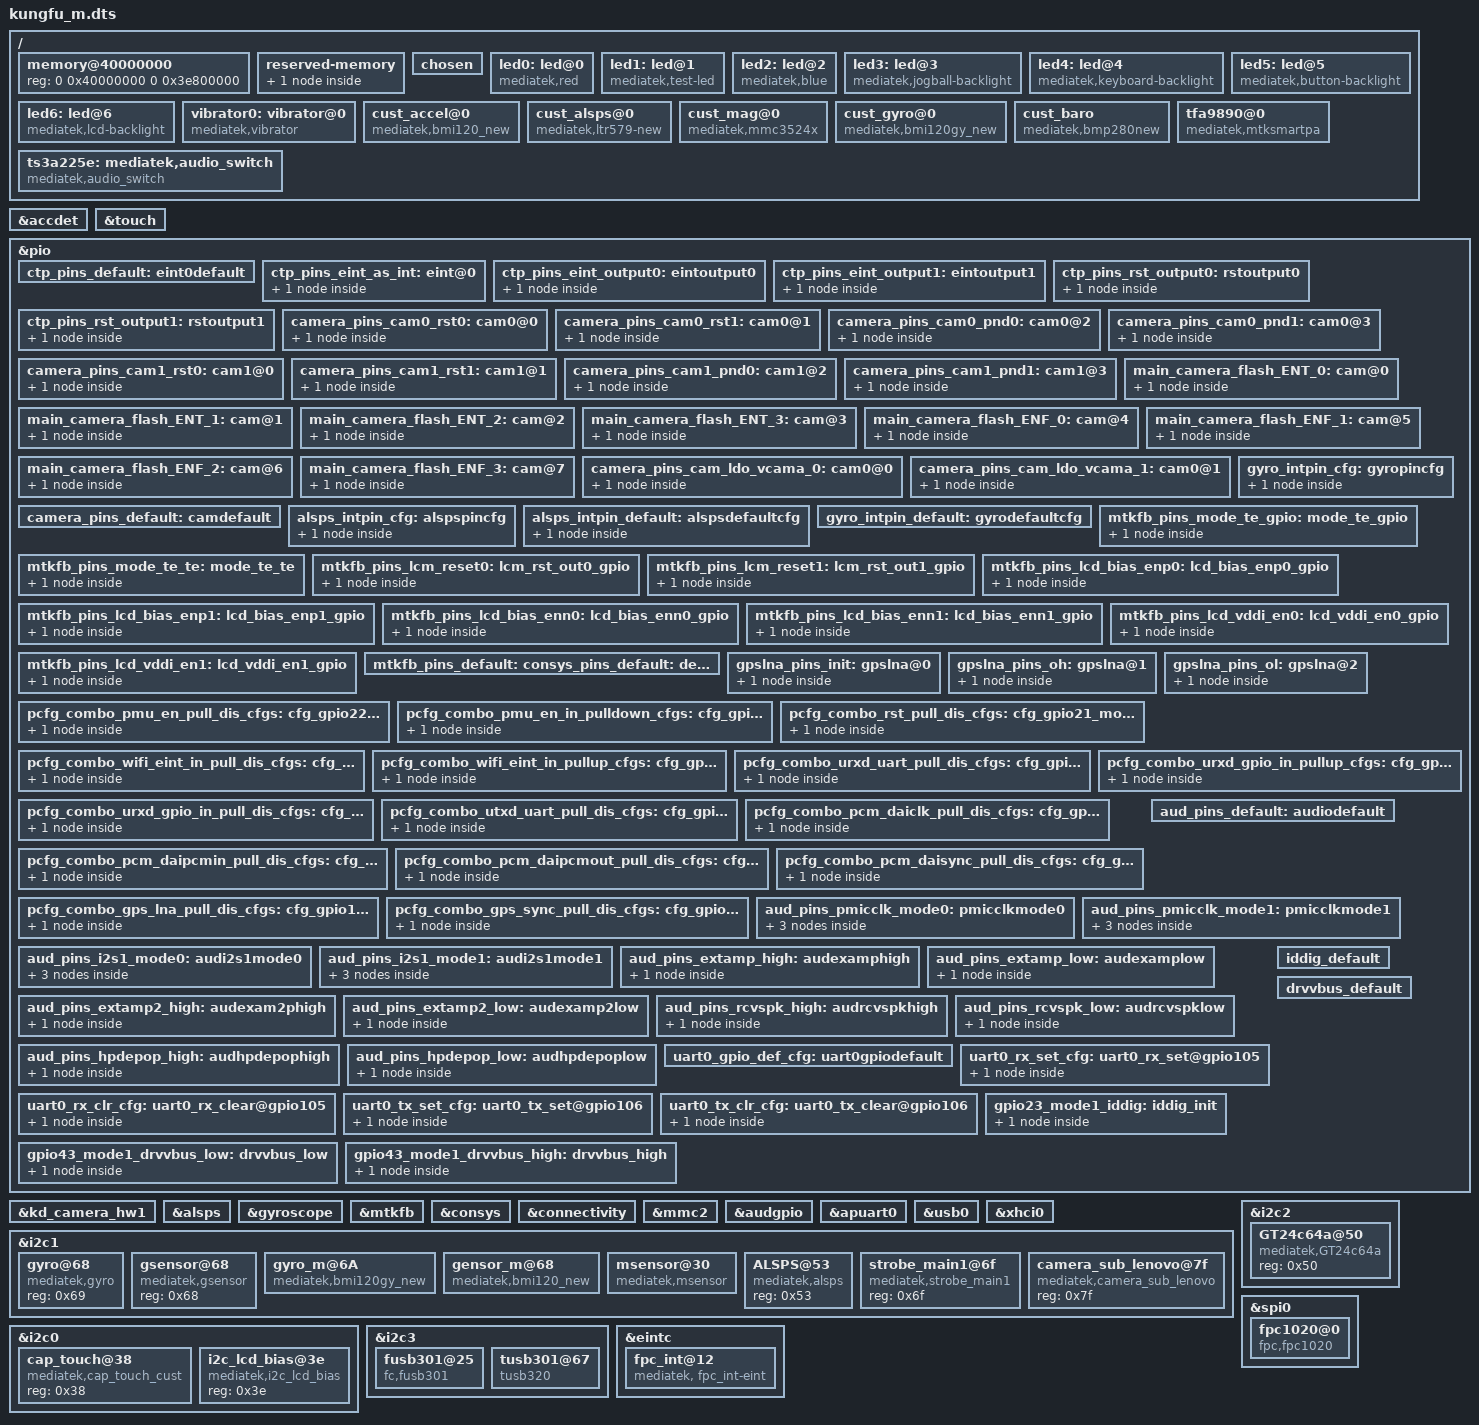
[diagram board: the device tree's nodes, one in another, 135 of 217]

/dts-v1/;

#include "mt6755.dtsi"
#include "cust.dtsi"

/ {
	memory@40000000 {
		device_type = "memory";
		reg = <0 0x40000000 0 0x3e800000>;
	};
	reserved-memory {
		#address-cells = <2>;
		#size-cells = <2>;
		ranges;

		reserve-memory-ccci_md3_ccif {
			compatible = "mediatek,reserve-memory-ccci_md3_ccif";
			no-map;
			size = <0 0x01000000>;
			alignment = <0 0x2000000>;
			alloc-ranges = <0 0x40000000 0 0xc0000000>;
		};
	};

	/* chosen */
	chosen {
		bootargs = "console=tty0 console=ttyMT0,921600n1 root=/dev/ram initrd=0x44000000,0x4B434E loglevel=8";

		/* fpga may has no lk, we need to specify display info here */
		/* fb buffer is reserved using this dts by memory node above */
		atag,videolfb-fb_base_h = <0x0>;
		atag,videolfb-fb_base_l = <0x7E800000>;
		atag,videolfb-islcmfound = <1>;
		/* because no lk, so lcm is not inited */
		atag,videolfb-islcm_inited = <0>;
		atag,videolfb-fps= <6000>;
		atag,videolfb-vramSize= <0x01800000>;
		atag,videolfb-lcmname= "nt35695_fhd_dsi_cmd_truly_nt50358_drv";
	};
	led0:led@0 {
		compatible = "mediatek,red";
		led_mode = <0>;
		data = <1>;
		pwm_config = <0 0 0 0 0>;
	};
	led1:led@1 {
		compatible = "mediatek,test-led";
		led_mode = <3>;
		data = <1>;
		pwm_config = <0 0 0 0 0>;
	};
	led2:led@2 {
		compatible = "mediatek,blue";
		led_mode = <0>;
		data = <2>;
		pwm_config = <0 0 0 0 0>;
	};
	led3:led@3 {
		compatible = "mediatek,jogball-backlight";
		led_mode = <0>;
		data = <1>;
		pwm_config = <0 0 0 0 0>;
	};
	led4:led@4 {
		compatible = "mediatek,keyboard-backlight";
		led_mode = <0>;
		data = <1>;
		pwm_config = <0 0 0 0 0>;
	};
	led5:led@5 {
		compatible = "mediatek,button-backlight";
		led_mode = <0>;
		data = <3>;
		pwm_config = <0 0 0 0 0>;
	};
	led6:led@6 {
		compatible = "mediatek,lcd-backlight";
		led_mode = <4>;/* lenovo-sw wuwl10 20160322 modify */
		data = <1>;
		pwm_config = <0 0 0 0 0>;
	};
	vibrator0:vibrator@0 {
		compatible = "mediatek,vibrator";
		vib_timer = <25>;
		vib_limit = <9>;
		vib_vol= <6>;
	};
/*  start sensor */
/* Lenovo-sw, weimh1, 2016-3-31 add begin: configure gsensor cust_accel */
	cust_accel@0 {
		compatible = "mediatek,bmi120_new";
		i2c_num	= <1>;
		i2c_addr = <0x6A 0 0 0>;   /*false addr,real is 0x68*/
		direction = <2>;
		power_id = <0xffff>;
		power_vol = <0>;
		firlen = <0>;
		is_batch_supported = <0>;
	};
/* Lenovo-sw, weimh1, 2016-3-31 add end: configure gsensor cust_accel */

	/*Begin, lenovo-sw lumy1*/
	cust_alsps@0 {
		compatible		= "mediatek,ltr579-new";
		i2c_num			= <1>;
		i2c_addr		= <0x53 0 0 0>;
		polling_mode_ps		= <0>;
		polling_mode_als	= <1>;
		power_id		= <0xffff>;
		power_vol		= <0>;
/* Total has 15 level*/
		als_level     = <0 3 10 30 100 200 350 500 800 1200 2000 4000 10000 30000 57937>;
/*  Total has 16 range*/
		als_value   = <0 1 8 26 80 170 320 450 730 1020 1800 3600  8500 26000 40000 40000>;
		ps_threshold_high	=  <200>;
		ps_threshold_low	=  <120>;
		is_batch_supported_ps	= <1>;
		is_batch_supported_als	= <1>;
	};
	/*End, lenovo-sw lumy1*/

/*lenovo-sw caoyi1 modify Msensor begin*/
	cust_mag@0 {
		compatible			= "mediatek,mmc3524x";
		i2c_num				= <1>;
		i2c_addr			= <0x30 0 0 0>;
		direction			= <4>;
		power_id			= <0xffff>;
		power_vol			= <0>;
		/* is_batch_supported		= <0>; */
	};
/*lenovo-sw caoyi1 modify Msensor end*/

/* Lenovo-sw, weimh1, 2016-4-4 add begin: configure gyroscope cust_gyro */
	cust_gyro@0 {
		compatible				= "mediatek,bmi120gy_new";
		i2c_num					= <1>;
		i2c_addr				= <0x68 0 0 0>;
		direction				= <2>;
		power_id				= <0xffff>;
		power_vol				= <0>;
		firlen					= <0>;
		is_batch_supported			= <0>;
	};
/* Lenovo-sw, weimh1, 2016-4-4 add end: configure gyroscope cust_gyro */

	cust_baro {
		compatible			= "mediatek,bmp280new";
		i2c_num				= <1>;
		/* i2c_addr			= <0x68 0 0 0>; */
		direction			= <0>;
		power_id			= <0xffff>;
		power_vol			= <0>;
		firlen				= <32>;
		is_batch_supported		= <0>;
	};
/* end sensor */
/* Lenovo-sw, chengx2, 2016-4-20 add for smartpa start */
	tfa9890@0 {
			compatible = "mediatek,mtksmartpa";
			
		};
	ts3a225e:mediatek,audio_switch {
			compatible = "mediatek,audio_switch";
		};

/* Lenovo-sw, chengx2, 2016-4-20 add for smartpa end */

};
&accdet {
		accdet-mic-vol = <7>;
		headset-mode-setting = <0x500 0x500 1 0x3F0 0x800 0x800 0x2000>;
		accdet-plugout-debounce = <20>;
		/*1:ACC mode, 2:low cost without in bias, 6:low cost with in bias*/
		accdet-mic-mode = <1>;
		/*0--MD_MAX--UP_MAX--DW_MAX*/
		headset-three-key-threshold = <0 80 200 500>;
		/*0--MD_MAX--VOICE_MAX--UP_MAX--DW_MAX*/
		headset-four-key-threshold = <0 58 121 192 450>;
};

/* TOUCH start */
&touch {
	tpd-resolution = <1080 1920>;
	interrupt-parent = <&eintc>;
	interrupts = <1 2>;
	debounce = <1 0>;
	use-tpd-button = <1>;
	tpd-key-num = <3>;
	tpd-key-local= <139 172 158 0>;
	tpd-key-dim-local = <90 883 100 40 230 883 100 40 370 883 100 40 0 0 0 0>;
	tpd-max-touch-num = <5>;
	tpd-filter-enable = <1>;
	tpd-filter-pixel-density = <146>;
	tpd-filter-custom-prameters = <0 0 0 0 0 0 0 0 0 0 0 0>;
	tpd-filter-custom-speed = <0 0 0>;
	pinctrl-names = "default", "state_eint_as_int", "state_eint_output0", "state_eint_output1",
		"state_rst_output0", "state_rst_output1";
	pinctrl-0 = <&ctp_pins_default>;
	pinctrl-1 = <&ctp_pins_eint_as_int>;
	pinctrl-2 = <&ctp_pins_eint_output0>;
	pinctrl-3 = <&ctp_pins_eint_output1>;
	pinctrl-4 = <&ctp_pins_rst_output0>;
	pinctrl-5 = <&ctp_pins_rst_output1>;
	status = "okay";
};
&pio {
	ctp_pins_default: eint0default {
	};
	ctp_pins_eint_as_int: eint@0 {
		pins_cmd_dat {
			pins = <PINMUX_GPIO1__FUNC_GPIO1>;
			slew-rate = <0>;
			bias-disable;
		};
	};
	ctp_pins_eint_output0: eintoutput0 {
		pins_cmd_dat {
			pins = <PINMUX_GPIO1__FUNC_GPIO1>;
			slew-rate = <1>;
			output-low;
		};
	};
	ctp_pins_eint_output1: eintoutput1 {
		pins_cmd_dat {
			pins = <PINMUX_GPIO1__FUNC_GPIO1>;
			slew-rate = <1>;
			output-high;
		};
	};
	ctp_pins_rst_output0: rstoutput0 {
		pins_cmd_dat {
			pins = <PINMUX_GPIO10__FUNC_GPIO10>;
			slew-rate = <1>;
			output-low;
		};
	};
	ctp_pins_rst_output1: rstoutput1 {
		pins_cmd_dat {
			pins = <PINMUX_GPIO10__FUNC_GPIO10>;
			slew-rate = <1>;
			output-high;
		};
	};
};
/* TOUCH end */

/* CAMERA GPIO standardization */
&pio {
	camera_pins_cam0_rst0: cam0@0 {
	    pins_cmd_dat {
			pins = <PINMUX_GPIO107__FUNC_GPIO107>;
			slew-rate = <1>; /*direction 0:in, 1:out*/
			output-low;/*direction out used only. output_low or high*/
		};
	};
	camera_pins_cam0_rst1: cam0@1 {
	    pins_cmd_dat {
			pins = <PINMUX_GPIO107__FUNC_GPIO107>;
			slew-rate = <1>;
			output-high;
		};
	};
	camera_pins_cam0_pnd0: cam0@2 {
	    pins_cmd_dat {
			pins = <PINMUX_GPIO110__FUNC_GPIO110>;
			slew-rate = <1>;
			output-low;
		};
	};
	camera_pins_cam0_pnd1: cam0@3 {
	    pins_cmd_dat {
			pins = <PINMUX_GPIO110__FUNC_GPIO110>;
			slew-rate = <1>;
			output-high;
		};
	};
	camera_pins_cam1_rst0: cam1@0 {
	    pins_cmd_dat {
			pins = <PINMUX_GPIO108__FUNC_GPIO108>;
			slew-rate = <1>; /*direction 0:in, 1:out*/
			output-low;/*direction out used only. output_low or high*/
		};
	};
	camera_pins_cam1_rst1: cam1@1 {
	    pins_cmd_dat {
			pins = <PINMUX_GPIO108__FUNC_GPIO108>;
			slew-rate = <1>;
			output-high;
		};
	};
	camera_pins_cam1_pnd0: cam1@2 {
	    pins_cmd_dat {
			pins = <PINMUX_GPIO111__FUNC_GPIO111>;
			slew-rate = <1>;
			output-low;
		};
	};
	camera_pins_cam1_pnd1: cam1@3 {
	    pins_cmd_dat {
			pins = <PINMUX_GPIO111__FUNC_GPIO111>;
			slew-rate = <1>;
			output-high;
		};
	};
	main_camera_flash_ENT_0: cam@0 {
		pins_cmd_dat {
			pins = <PINMUX_GPIO8__FUNC_GPIO8>;
			slew-rate = <1>;
			output-low;
		};
	};
	main_camera_flash_ENT_1: cam@1 {
		pins_cmd_dat {
			pins = <PINMUX_GPIO8__FUNC_GPIO8>;
			slew-rate = <1>;
			output-high;
		};
	};
	main_camera_flash_ENT_2: cam@2 {
		pins_cmd_dat {
			pins = <PINMUX_GPIO9__FUNC_GPIO9>;
			slew-rate = <1>;
			output-low;
                };
	};
	main_camera_flash_ENT_3: cam@3 {
		pins_cmd_dat {
			pins = <PINMUX_GPIO9__FUNC_GPIO9>;
			slew-rate = <1>;
			output-high;
                };
	};
	main_camera_flash_ENF_0: cam@4{
		pins_cmd_dat {
			pins = <PINMUX_GPIO19__FUNC_GPIO19>;
			slew-rate = <1>;
			output-low;
		};
	};
	main_camera_flash_ENF_1: cam@5 {
		pins_cmd_dat {
			pins = <PINMUX_GPIO19__FUNC_GPIO19>;
			slew-rate = <1>;
			output-high;
		};
	};
	main_camera_flash_ENF_2: cam@6 {
		pins_cmd_dat {
			pins = <PINMUX_GPIO9__FUNC_GPIO9>;
			slew-rate = <1>;
			output-low;
		};
	};
	main_camera_flash_ENF_3: cam@7{
		pins_cmd_dat {
			pins = <PINMUX_GPIO9__FUNC_GPIO9>;
			slew-rate = <1>;
			output-high;
		};
	};
camera_pins_cam_ldo_vcama_0: cam0@0 {
	    pins_cmd_dat {
			pins = <PINMUX_GPIO83__FUNC_GPIO83>;
			slew-rate = <1>; /*direction 0:in, 1:out*/
			output-low;/*direction out used only. output_low or high*/
		};
	};
	camera_pins_cam_ldo_vcama_1: cam0@1 {
	    pins_cmd_dat {
			pins = <PINMUX_GPIO83__FUNC_GPIO83>;
			slew-rate = <1>;
			output-high;
		};
	};
	camera_pins_default: camdefault {
	};

};

&kd_camera_hw1 {
	pinctrl-names = "default",
			"cam0_rst0", "cam0_rst1", "cam0_pnd0", "cam0_pnd1",
			"cam1_rst0", "cam1_rst1", "cam1_pnd0", "cam1_pnd1",
			"flash_ENT0", "flash_ENT1", "flash_ENT2", "flash_ENT3","flash_ENF0", "flash_ENF1","flash_ENF2", "flash_ENF3","cam_ldo_vcama_0", "cam_ldo_vcama_1";
			/*"cam2_rst0", "cam2_rst1", "cam2_pnd0", "cam2_pnd1",
			"cam_ldo_vcama_0", "cam_ldo_vcama_1";*/
	pinctrl-0 = <&camera_pins_default>;
	pinctrl-1 = <&camera_pins_cam0_rst0>;
	pinctrl-2 = <&camera_pins_cam0_rst1>;
	pinctrl-3 = <&camera_pins_cam0_pnd0>;
	pinctrl-4 = <&camera_pins_cam0_pnd1>;
	pinctrl-5 = <&camera_pins_cam1_rst0>;
	pinctrl-6 = <&camera_pins_cam1_rst1>;
	pinctrl-7 = <&camera_pins_cam1_pnd0>;
	pinctrl-8 = <&camera_pins_cam1_pnd1>;
	pinctrl-9 = <&main_camera_flash_ENT_0>;
	pinctrl-10 = <&main_camera_flash_ENT_1>;
	pinctrl-11 = <&main_camera_flash_ENT_2>;
	pinctrl-12 = <&main_camera_flash_ENT_3>;
	pinctrl-13 = <&main_camera_flash_ENF_0>;
	pinctrl-14 = <&main_camera_flash_ENF_1>;
	pinctrl-15 = <&main_camera_flash_ENF_2>;
	pinctrl-16 = <&main_camera_flash_ENF_3>;
	pinctrl-17 = <&camera_pins_cam_ldo_vcama_0>;
	pinctrl-18 = <&camera_pins_cam_ldo_vcama_1>;
	status = "okay";

};
/* CAMERA GPIO end */

&pio {	/*Begin, lenovo-sw lumy1*/
	alsps_intpin_cfg: alspspincfg {

		pins_cmd_dat {
			pins = <PINMUX_GPIO6__FUNC_GPIO6>;
			slew-rate = <0>;
			bias-pull-up = <00>;
		};
	};

	alsps_intpin_default: alspsdefaultcfg {
		pins_cmd_dat {
			pins = <PINMUX_GPIO6__FUNC_GPIO6>;
			slew-rate = <0>;
			bias-pull-up = <00>;
		};
	};
	/*End, lenovo-sw lumy1*/
	gyro_intpin_cfg: gyropincfg {

		pins_cmd_dat {
			pins = <PINMUX_GPIO4__FUNC_GPIO4>;
			slew-rate = <0>;
			bias-pull-down = <00>;
		};
	};

	gyro_intpin_default: gyrodefaultcfg {

	};
};

&alsps {
	pinctrl-names = "pin_default", "pin_cfg";
	pinctrl-0 = <&alsps_intpin_default>;
	pinctrl-1 = <&alsps_intpin_cfg>;
	status = "okay";
};

&gyroscope {
	pinctrl-names = "pin_default", "pin_cfg";
	pinctrl-0 = <&gyro_intpin_default>;
	pinctrl-1 = <&gyro_intpin_cfg>;
	status = "okay";
};

/* DISPSYS GPIO standardization */
&pio {

	mtkfb_pins_mode_te_gpio: mode_te_gpio {
		pins_cmd_dat {
			pins = <PINMUX_GPIO44__FUNC_GPIO44>;
		};
	};

	mtkfb_pins_mode_te_te: mode_te_te {
		pins_cmd_dat {
			pins = <PINMUX_GPIO44__FUNC_DSI_TE>;
		};
	};

	mtkfb_pins_lcm_reset0: lcm_rst_out0_gpio {
		pins_cmd_dat {
			pins = <PINMUX_GPIO158__FUNC_GPIO158>;/* wuwl10 20160322 modify */
			slew-rate = <1>;
			output-low;
		};
	};

	mtkfb_pins_lcm_reset1: lcm_rst_out1_gpio {
		pins_cmd_dat {
			pins = <PINMUX_GPIO158__FUNC_GPIO158>;/* wuwl10 20160322 modify */
			slew-rate = <1>;
			output-high;
		};
	};

	mtkfb_pins_lcd_bias_enp0: lcd_bias_enp0_gpio {
		pins_cmd_dat {
			pins = <PINMUX_GPIO53__FUNC_GPIO53>;
			slew-rate = <1>;
			output-low;
		};
	};

	mtkfb_pins_lcd_bias_enp1: lcd_bias_enp1_gpio {
		pins_cmd_dat {
			pins = <PINMUX_GPIO53__FUNC_GPIO53>;
			slew-rate = <1>;
			output-high;
		};
	};

/* lenovo-sw wuwl10 20160322 modify begin */
	mtkfb_pins_lcd_bias_enn0: lcd_bias_enn0_gpio {
		pins_cmd_dat {
			pins = <PINMUX_GPIO104__FUNC_GPIO104>;
			slew-rate = <1>;
			output-low;
		};
	};

	mtkfb_pins_lcd_bias_enn1: lcd_bias_enn1_gpio {
		pins_cmd_dat {
			pins = <PINMUX_GPIO104__FUNC_GPIO104>;
			slew-rate = <1>;
			output-high;
		};
	};
	mtkfb_pins_lcd_vddi_en0: lcd_vddi_en0_gpio {
		pins_cmd_dat {
			pins = <PINMUX_GPIO61__FUNC_GPIO61>;
			slew-rate = <1>;
			output-low;
		};
	};

	mtkfb_pins_lcd_vddi_en1: lcd_vddi_en1_gpio {
		pins_cmd_dat {
			pins = <PINMUX_GPIO61__FUNC_GPIO61>;
			slew-rate = <1>;
			output-high;
		};
	};
/* lenovo-sw wuwl10 20160322 modify end */

	mtkfb_pins_default: default {
	};
};

&mtkfb {
	pinctrl-names = "default", "mode_te_gpio", "mode_te_te", "lcm_rst_out0_gpio",
/* lenovo-sw wuwl10 20160322 modify begin */
	"lcm_rst_out1_gpio", "lcd_bias_enp0_gpio", "lcd_bias_enp1_gpio",
	"lcd_bias_enn0_gpio", "lcd_bias_enn1_gpio", "lcd_vddi_en0_gpio", "lcd_vddi_en1_gpio";
	pinctrl-0 = <&mtkfb_pins_default>;
	pinctrl-1 = <&mtkfb_pins_mode_te_gpio>;
	pinctrl-2 = <&mtkfb_pins_mode_te_te>;
	pinctrl-3 = <&mtkfb_pins_lcm_reset0>;
	pinctrl-4 = <&mtkfb_pins_lcm_reset1>;
	pinctrl-5 = <&mtkfb_pins_lcd_bias_enp0>;
	pinctrl-6 = <&mtkfb_pins_lcd_bias_enp1>;
	pinctrl-7 = <&mtkfb_pins_lcd_bias_enn0>;
	pinctrl-8 = <&mtkfb_pins_lcd_bias_enn1>;
	pinctrl-9 = <&mtkfb_pins_lcd_vddi_en0>;
	pinctrl-10 = <&mtkfb_pins_lcd_vddi_en1>;
/* lenovo-sw wuwl10 20160322 modify end */
	status = "okay";
};/* DISPSYS GPIO standardization end */
/* CONSYS GPIO standardization */
&pio {
	consys_pins_default: default {
	};

	gpslna_pins_init: gpslna@0 {
		pins_cmd_dat {
			pins = <PINMUX_GPIO114__FUNC_GPIO114>;
			slew-rate = <0>;
			bias-disable;
			output-low;
		};
	};

	gpslna_pins_oh: gpslna@1 {
		pins_cmd_dat {
			pins = <PINMUX_GPIO114__FUNC_GPIO114>;
			slew-rate = <1>;
			output-high;
		};
	};

	gpslna_pins_ol: gpslna@2 {
		pins_cmd_dat {
			pins = <PINMUX_GPIO114__FUNC_GPIO114>;
			slew-rate = <1>;
			output-low;
		};
	};
};

&consys {
	pinctrl-names = "default", "gps_lna_state_init", "gps_lna_state_oh", "gps_lna_state_ol";
	pinctrl-0 = <&consys_pins_default>;
	pinctrl-1 = <&gpslna_pins_init>;
	pinctrl-2 = <&gpslna_pins_oh>;
	pinctrl-3 = <&gpslna_pins_ol>;
	status = "okay";
};
/* CONSYS end */
/* lenovo-sw chengx2 modify for wcn begin */
/* Connectivity GPIO standardization */
&pio {
	pcfg_combo_pmu_en_pull_dis_cfgs:cfg_gpio22_model_pull_dis {
		combo_pins {
			pins = <PINMUX_GPIO22__FUNC_GPIO22>;
			bias-disable;
		};
	};
	pcfg_combo_pmu_en_in_pulldown_cfgs:cfg_gpio22_model_in_pulldown {
		combo_pins {
			pins = <PINMUX_GPIO22__FUNC_GPIO22>;
			bias-pull-down;
		};
	};
	pcfg_combo_rst_pull_dis_cfgs:cfg_gpio21_model_in_pull_dis {
		combo_pins {
			pins = <PINMUX_GPIO21__FUNC_GPIO21>;
			bias-disable;
		};
	};
	pcfg_combo_wifi_eint_in_pull_dis_cfgs:cfg_gpio18_model_in_pull_dis {
		combo_pins {
			pins = <PINMUX_GPIO18__FUNC_GPIO18>;
			slew-rate = <0>;
			bias-disable;
		};
	};
	pcfg_combo_wifi_eint_in_pullup_cfgs:cfg_gpio18_model_in_pullup {
		combo_pins {
			pins = <PINMUX_GPIO18__FUNC_GPIO18>;
			slew-rate = <0>;
			bias-pull-up = <00>;
		};
	};
	pcfg_combo_urxd_uart_pull_dis_cfgs:cfg_gpio118_model_pull_dis {
		combo_pins {
			pins = <PINMUX_GPIO118__FUNC_PTA_RXD>;
			bias-disable;
		};
	};
	pcfg_combo_urxd_gpio_in_pullup_cfgs:cfg_gpio118_model_in_pullup {
		combo_pins {
			pins = <PINMUX_GPIO118__FUNC_PTA_RXD>;
			slew-rate = <0>;
			bias-pull-up = <00>;
		};
	};
	pcfg_combo_urxd_gpio_in_pull_dis_cfgs:cfg_gpio118_model_in_pull_dis {
		combo_pins {
			pins = <PINMUX_GPIO118__FUNC_PTA_RXD>;
			slew-rate = <0>;
			bias-disable;
		};
	};
	pcfg_combo_utxd_uart_pull_dis_cfgs:cfg_gpio117_model_pull_dis {
		combo_pins {
			pins = <PINMUX_GPIO117__FUNC_PTA_TXD>;
			bias-disable;
		};
	};
	pcfg_combo_pcm_daiclk_pull_dis_cfgs:cfg_gpio14_mode5_pull_dis {
		combo_pins {
			pins = <PINMUX_GPIO14__FUNC_MRG_CLK>;
			bias-disable;
		};
	};
	pcfg_combo_pcm_daipcmin_pull_dis_cfgs:cfg_gpio16_mode5_pull_dis {
		combo_pins {
			pins = <PINMUX_GPIO16__FUNC_MRG_DI>;
			bias-disable;
		};
	};
	pcfg_combo_pcm_daipcmout_pull_dis_cfgs:cfg_gpio15_mode4_pull_dis {
		combo_pins {
			pins = <PINMUX_GPIO15__FUNC_MRG_DO>;
			bias-disable;
		};
	};
	pcfg_combo_pcm_daisync_pull_dis_cfgs:cfg_gpio13_mode4_pull_dis {
		combo_pins {
			pins = <PINMUX_GPIO13__FUNC_MRG_SYNC>;
			bias-disable;
		};
	};
	pcfg_combo_gps_lna_pull_dis_cfgs:cfg_gpio114_model_in_pull_dis {
		combo_pins {
			pins = <PINMUX_GPIO114__FUNC_GPIO114>;
			bias-disable;
		};
	};
	pcfg_combo_gps_sync_pull_dis_cfgs:cfg_gpio121_mode6_pull_dis {
		combo_pins {
			pins = <PINMUX_GPIO121__FUNC_AGPS_SYNC>;
			bias-disable;
		};
	};
};
&connectivity{
	pinctrl-names = "gpio_pmu_en_pull_dis",
		"gpio_pmu_en_in_pulldown", 
		"gpio_rst_pull_dis", 
		"gpio_wifi_eint_in_pull_dis",
		"gpio_wifi_eint_in_pullup",
		"gpio_urxd_uart_pull_dis",
		"gpio_urxd_gpio_in_pullup",
		"gpio_urxd_gpio_in_pull_dis",
		"gpio_utxd_uart_pull_dis",
		"gpio_pcm_daiclk_pull_dis",
		"gpio_pcm_daipcmin_pull_dis",
		"gpio_pcm_daipcmout_pull_dis", 
		"gpio_pcm_daisync_pull_dis",
		"gpio_gps_lna_pull_dis",
		"gpio_gps_sync_pull_dis";
	pinctrl-0 = <&pcfg_combo_pmu_en_pull_dis_cfgs>;
	pinctrl-1 = <&pcfg_combo_pmu_en_in_pulldown_cfgs>;
	pinctrl-2 = <&pcfg_combo_rst_pull_dis_cfgs>;
	pinctrl-3 = <&pcfg_combo_wifi_eint_in_pull_dis_cfgs>;
	pinctrl-4 = <&pcfg_combo_wifi_eint_in_pullup_cfgs>;
	pinctrl-5 = <&pcfg_combo_urxd_uart_pull_dis_cfgs>;
	pinctrl-6 = <&pcfg_combo_urxd_gpio_in_pullup_cfgs>;
	pinctrl-7 = <&pcfg_combo_urxd_gpio_in_pull_dis_cfgs>;
	pinctrl-8 = <&pcfg_combo_utxd_uart_pull_dis_cfgs>;
	pinctrl-9 = <&pcfg_combo_pcm_daiclk_pull_dis_cfgs>;
	pinctrl-10 = <&pcfg_combo_pcm_daipcmin_pull_dis_cfgs>;
	pinctrl-11 = <&pcfg_combo_pcm_daipcmout_pull_dis_cfgs>;
	pinctrl-12 = <&pcfg_combo_pcm_daisync_pull_dis_cfgs>;
	pinctrl-13 = <&pcfg_combo_gps_lna_pull_dis_cfgs>;
	pinctrl-14 = <&pcfg_combo_gps_sync_pull_dis_cfgs>;
};
/* Connectivity end */
&mmc2 {
		status = "okay";
};
/* lenovo-sw chengx2 modify for wcn end */
/* AUDIO GPIO standardization */
&audgpio {
	pinctrl-names = "default", "audpmicclk-mode0", "audpmicclk-mode1",
		"audi2s1-mode0", "audi2s1-mode1", "extamp-pullhigh", "extamp-pulllow",
		"extamp2-pullhigh", "extamp2-pulllow", "rcvspk-pullhigh",
		"rcvspk-pulllow","hpdepop-pullhigh","hpdepop-pulllow";
	pinctrl-0 = <&aud_pins_default>;
	pinctrl-1 = <&aud_pins_pmicclk_mode0>;
	pinctrl-2 = <&aud_pins_pmicclk_mode1>;
	pinctrl-3 = <&aud_pins_i2s1_mode0>;
	pinctrl-4 = <&aud_pins_i2s1_mode1>;
	pinctrl-5 = <&aud_pins_extamp_high>;
	pinctrl-6 = <&aud_pins_extamp_low>;
	pinctrl-7 = <&aud_pins_extamp2_high>;
	pinctrl-8 = <&aud_pins_extamp2_low>;
	pinctrl-9 = <&aud_pins_rcvspk_high>;
	pinctrl-10 = <&aud_pins_rcvspk_low>;
	pinctrl-11 = <&aud_pins_hpdepop_high>;
	pinctrl-12 = <&aud_pins_hpdepop_low>;
	status = "okay";
};

&pio {
	aud_pins_default: audiodefault {
	};

	aud_pins_pmicclk_mode0: pmicclkmode0 {
		pins_cmd0_dat {
			pins = <PINMUX_GPIO149__FUNC_GPIO149>;
		};
		pins_cmd1_dat {
			pins = <PINMUX_GPIO150__FUNC_GPIO150>;
			slew-rate = <0>;
			bias-pull-up = <00>;
		};
		pins_cmd2_dat {
			pins = <PINMUX_GPIO151__FUNC_GPIO151>;
		};
	};

	aud_pins_pmicclk_mode1: pmicclkmode1 {
		pins_cmd0_dat {
			pins = <PINMUX_GPIO149__FUNC_AUD_CLK_MOSI>;
		};
		pins_cmd1_dat {
			pins = <PINMUX_GPIO150__FUNC_AUD_DAT_MOSI>;
		};
		pins_cmd2_dat {
			pins = <PINMUX_GPIO151__FUNC_AUD_DAT_MISO>;
		};
	};

	aud_pins_i2s1_mode0: audi2s1mode0 {
		pins_cmd0_dat {
			pins = <PINMUX_GPIO7__FUNC_GPIO7>;
		};
		pins_cmd1_dat {
			pins = <PINMUX_GPIO6__FUNC_GPIO6>;
		};
		pins_cmd2_dat {
			pins = <PINMUX_GPIO5__FUNC_GPIO5>;
		};
	};

	aud_pins_i2s1_mode1: audi2s1mode1 {
		pins_cmd0_dat {
			pins = <PINMUX_GPIO7__FUNC_I2S0_DI>;
		};
		pins_cmd1_dat {
			pins = <PINMUX_GPIO6__FUNC_I2S0_LRCK>;
		};
		pins_cmd2_dat {
			pins = <PINMUX_GPIO5__FUNC_I2S0_BCK>;
		};
	};

	aud_pins_extamp_high: audexamphigh {
		pins_cmd_dat {
			pins = <PINMUX_GPIO115__FUNC_GPIO115>;
			slew-rate = <1>;
			output-high;
		};
	};

	aud_pins_extamp_low: audexamplow {
		pins_cmd_dat {
			pins = <PINMUX_GPIO115__FUNC_GPIO115>;
			slew-rate = <1>;
			output-low;
		};
	};

	aud_pins_extamp2_high: audexam2phigh {
		pins_cmd_dat {
			pins = <PINMUX_GPIO54__FUNC_GPIO54>;
			slew-rate = <1>;
			output-high;
		};
	};
	aud_pins_extamp2_low: audexamp2low {
		pins_cmd_dat {
			pins = <PINMUX_GPIO54__FUNC_GPIO54>;
			slew-rate = <1>;
			output-low;
		};
	};

	aud_pins_rcvspk_high: audrcvspkhigh {
		pins_cmd_dat {
			pins = <PINMUX_GPIO120__FUNC_GPIO120>;
			slew-rate = <1>;
			output-high;
		};
	};

	aud_pins_rcvspk_low: audrcvspklow {
		pins_cmd_dat {
			pins = <PINMUX_GPIO120__FUNC_GPIO120>;
			slew-rate = <1>;
			output-low;
		};
	};

	aud_pins_hpdepop_high: audhpdepophigh {
		pins_cmd_dat {
			pins = <PINMUX_GPIO24__FUNC_GPIO24>;
			slew-rate = <1>;
			output-high;
		};
	};

	aud_pins_hpdepop_low: audhpdepoplow {
		pins_cmd_dat {
			pins = <PINMUX_GPIO24__FUNC_GPIO24>;
			slew-rate = <1>;
			output-low;
		};
	};
};
/* AUDIO GPIO end */

/* UART GPIO */
&apuart0 {
	pinctrl-names = "uart0_gpio_default",
			"uart0_rx_set",
			"uart0_rx_clear",
			"uart0_tx_set",
			"uart0_tx_clear";
	pinctrl-0 = <&uart0_gpio_def_cfg>;
	pinctrl-1 = <&uart0_rx_set_cfg>;
	pinctrl-2 = <&uart0_rx_clr_cfg>;
	pinctrl-3 = <&uart0_tx_set_cfg>;
	pinctrl-4 = <&uart0_tx_clr_cfg>;
	status = "okay";
};

&pio {
	/* UART GPIO Settings - Start */
	/* UART0: rx set, rx clear, tx clear, tx clear*/
	uart0_gpio_def_cfg:uart0gpiodefault {

	};
	uart0_rx_set_cfg:uart0_rx_set@gpio105 {
		pins_cmd_dat {
			pins = <PINMUX_GPIO105__FUNC_URXD0>;
		};
	};
	uart0_rx_clr_cfg:uart0_rx_clear@gpio105  {
		pins_cmd_dat {
			pins = <PINMUX_GPIO105__FUNC_GPIO105>;
			slew-rate = <1>;
			output-high;
		};
	};
	uart0_tx_set_cfg:uart0_tx_set@gpio106  {
		pins_cmd_dat {
			pins = <PINMUX_GPIO106__FUNC_UTXD0>;
		};
	};
	uart0_tx_clr_cfg:uart0_tx_clear@gpio106  {
		pins_cmd_dat {
			pins = <PINMUX_GPIO106__FUNC_GPIO106>;
			slew-rate = <1>;
			output-high;
		};
	};
};/* UART GPIO end */

/* NFC GPIO standardization */
/*
&pio {
	nfc_default: default {

	};

	nfc_ven_high: state_ven_high {
		pins_cmd_dat {
			pins = <PINMUX_GPIO28__FUNC_GPIO28>;
			slew-rate = <1>;
			output-high;
		};
	};

	nfc_ven_low: state_ven_low {
		pins_cmd_dat {
			pins = <PINMUX_GPIO28__FUNC_GPIO28>;
			slew-rate = <1>;
			output-low;
		};
	};

	nfc_rst_high: state_rst_high {
		pins_cmd_dat {
			pins = <PINMUX_GPIO25__FUNC_GPIO25>;
			slew-rate = <1>;
			output-high;
		};
	};

	nfc_rst_low: state_rst_low {
		pins_cmd_dat {
			pins = <PINMUX_GPIO25__FUNC_GPIO25>;
			slew-rate = <1>;
			output-low;
		};
	};

	nfc_eint_high: state_eint_high {
		pins_cmd_dat {
			pins = <PINMUX_GPIO27__FUNC_GPIO27>;
			slew-rate = <1>;
			output-high;
		};
	};

	nfc_eint_low: state_eint_low {
		pins_cmd_dat {
			pins = <PINMUX_GPIO27__FUNC_GPIO27>;
			slew-rate = <1>;
			output-low;
		};
	};

	nfc_irq_init: state_irq_init {
		pins_cmd_dat {
			pins = <PINMUX_GPIO26__FUNC_GPIO26>;
			slew-rate = <0>;
			bias-pull-down = <00>;
		};
	};
};

&nfc {
	pinctrl-names = "default", "ven_high", "ven_low", "rst_high", "rst_low", "eint_high", "eint_low", "irq_init";
	pinctrl-0 = <&nfc_default>;
	pinctrl-1 = <&nfc_ven_high>;
	pinctrl-2 = <&nfc_ven_low>;
	pinctrl-3 = <&nfc_rst_high>;
	pinctrl-4 = <&nfc_rst_low>;
	pinctrl-5 = <&nfc_eint_high>;
	pinctrl-6 = <&nfc_eint_low>;
	pinctrl-7 = <&nfc_irq_init>;
	status = "okay";
};
*//*chengx2*/
/* NFC end */

&pio {
	iddig_default: iddig_default {
	};

	gpio23_mode1_iddig: iddig_init {
		pins_cmd_dat {
			pins = <PINMUX_GPIO23__FUNC_IDDIG>;
			slew-rate = <0>;
			bias-pull-up = <00>;
		};
	};
};

&pio {
	drvvbus_default: drvvbus_default {
	};

	gpio43_mode1_drvvbus_low: drvvbus_low {
		pins_cmd_dat {
			pins = <PINMUX_GPIO43__FUNC_USB_DRVVBUS>;
			slew-rate = <1>;
			output-low;
		};
	};

	gpio43_mode1_drvvbus_high: drvvbus_high {
		pins_cmd_dat {
			pins = <PINMUX_GPIO43__FUNC_USB_DRVVBUS>;
			slew-rate = <1>;
			output-high;
		};
	};
};

&usb0 {
	pinctrl-names = "iddig_default", "iddig_init";
	pinctrl-0 = <&iddig_default>;
	pinctrl-1 = <&gpio23_mode1_iddig>;
	status = "okay";
};

&xhci0 {
	pinctrl-names = "drvvbus_default", "drvvbus_low", "drvvbus_high";
	pinctrl-0 = <&drvvbus_default>;
	pinctrl-1 = <&gpio43_mode1_drvvbus_low>;
	pinctrl-2 = <&gpio43_mode1_drvvbus_high>;
	status = "okay";
};

&i2c1 {

	gyro@68 {
		compatible = "mediatek,gyro";
		reg = <0x69>;
		status = "okay";
	};

	gsensor@68 {
		compatible = "mediatek,gsensor";
		reg = <0x68>;
		status = "okay";
	};

	/* Lenovo-sw, weimh1, 2016-3-31 add begin: configure gsensor i2c1 */
	gyro_m@6A {
		compatible = "mediatek,bmi120gy_new";
		i2c_num	= <1>;
		reg = <0x68>;
		direction = <2>;
		status = "okay";
	};

	gensor_m@68 {
		compatible = "mediatek,bmi120_new";
		i2c_num	= <1>;
		reg = <0x6A>;
		direction = <2>;
		status = "okay";
	};
	/* Lenovo-sw, weimh1, 2016-3-31 add end: configure gsensor i2c1 */

/*lenovo-sw caoyi1 modify Msensor begin*/
	msensor@30 {
		compatible = "mediatek,msensor";
		i2c_num	= <1>;
		reg = <0x30>;
		status = "okay";
	};
/*lenovo-sw caoyi1 modify Msensor end*/

/*Begin, lenovo-sw lumy1*/
	ALSPS@53 {
		compatible = "mediatek,alsps";
		reg = <0x53>;
		status = "okay";
	};
/*End, lenovo-sw lumy1*/

	strobe_main1@6f{
		compatible = "mediatek,strobe_main1";
		reg = <0x6f>;
	};

};

/*lenovo.sw wuyt3 add for k52M camera*/
&i2c2 {

GT24c64a@50 {
			compatible = "mediatek,GT24c64a";
			reg = <0x50>;
			status = "okay";
		};
};

&i2c1{
		camera_sub_lenovo@7f {
			compatible = "mediatek,camera_sub_lenovo";
			reg = <0x7f>;
			status = "okay";
		};


};

/*lenovo.sw wuyt3 add end*/
		
/* IRTX GPIO end */
#if 0
&apirtx {
	pinctrl-names = "irtx_gpio_led_default",
			"irtx_gpio_led_set",
			"irtx_gpio_en_default",
			"irtx_gpio_en_set";

	pinctrl-0 = <&irtx_gpio_led_default>;
	pinctrl-1 = <&irtx_gpio_led_set>;
	pinctrl-2 = <&irtx_gpio_en_default>;
	pinctrl-3 = <&irtx_gpio_en_set>;
	status = "okay";
};
&pio {
	/* IRTX GPIO Settings -Start */
	/* default: GPIO0, output, high */
	irtx_gpio_led_default:irtx_gpio_led_def@gpio116 {
		pins_cmd_dat {
			pins = <PINMUX_GPIO116__FUNC_GPIO116>;
			slew-rate = <1>;
			bias-disable;
			output-low;
			input-schmitt-enable = <0>;
		};
	};

	irtx_gpio_led_set:irtx_gpio_led_set@gpio116 {
		pins_cmd_dat {
			pins = <PINMUX_GPIO116__FUNC_IRTX_OUT>;
			slew-rate = <1>;
			output-high;
		};
	};

	irtx_gpio_en_default:irtx_gpio_en_def@gpio104 {
		pins_cmd_dat {
			pins = <PINMUX_GPIO104__FUNC_GPIO104>;
			slew-rate = <1>;
			bias-disable;
			output-low;
			input-schmitt-enable = <0>;
		};
	};

	irtx_gpio_en_set:irtx_gpio_en_set@gpio104 {
		pins_cmd_dat {
			pins = <PINMUX_GPIO104__FUNC_GPIO104>;
			slew-rate = <1>;
			output-high;
		};
	};


}; /* IRTX GPIO Settings -End */
#endif 

&i2c0 {
	cap_touch@38 {
		compatible = "mediatek,cap_touch_cust";
		reg = <0x38>;
	};
/*lenovo.sw wuwl10 20160420 add begin*/
	i2c_lcd_bias@3e {
		compatible = "mediatek,i2c_lcd_bias";
		reg = <0x3e>;
	};
/*lenovo.sw wuwl10 20160420 add end*/
};

/*lenovo-sw wengjun1 add for fusb301a configruation 20160420 begin*/
&i2c3 {
	fusb301@25 {
		status = "okay";
		compatible = "fc,fusb301";
		reg = <0x25>;
		vusb-supply = <&mt_pmic_vusb33_ldo_reg>;
		interrupt-parent = <&eintc>;
		interrupts = <24 0x2>;
		debounce = <24 0>;
		fusb301,int-gpio = <&pio 24 0>;
		fusb301,init-mode = /bits/ 8 <32>;
		fusb301,drp-toggle-time = /bits/ 8 <0>;
		fusb301,host-current = /bits/ 8 <1>;
		fusb301,use-try-snk-emulation;
		fusb301,ttry-timer-value = <250 600>;
		fusb301,ccdebounce-timer-value = <20 200>;
	};

	tusb301@67 {
		status = "okay";
		compatible = "tusb320";
		reg = <0x67>;
		interrupt-parent = <&eintc>;
		interrupts = <24 0x2>;
		debounce = <24 0>;
		tusb320,int-gpio = <&pio 24 0>;
	};
};
/*lenovo-sw wengjun1 add for fusb301a configruation 20160420 end*/

/* lenovo-sw, chenzz3, configure spi device for fingerprint, begin */
&spi0 {
	fpc1020@0 {
		status = "ok";
		compatible = "fpc,fpc1020";
		reg = <1>;
		spi-max-frequency = <4800000>;
		input-device-name = "fpc1020";
		fpc,gpio_rst      = <116>;
		fpc,gpio_irq      = <12>;
		fpc,use_fpc2050   = <1>;
		fpc,enable-on-boot;
		fpc,enable-wakeup;
		/* EV_MSC, MSC_SCAN */
		fpc,event-type = <4>;
		fpc,event-code = <4>;
	};
};

&eintc {
	fpc_int@12 {
		compatible = "mediatek, fpc_int-eint";
		interrupt-parent = <&eintc>;
		interrupts = <12 1>;
		debounce = <12 1000>;
	};
};
/* lenovo-sw, chenzz3, configure spi device for fingerprint, end */

